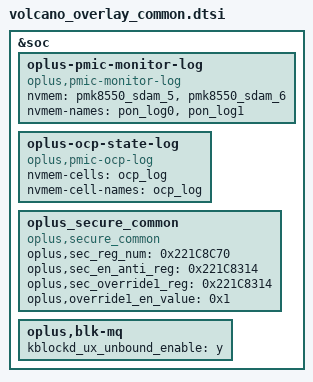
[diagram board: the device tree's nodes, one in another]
&soc {
    //add for 7635
   oplus-pmic-monitor-log {
        compatible = "oplus,pmic-monitor-log";
        nvmem = <&pmk8550_sdam_5>, <&pmk8550_sdam_6>;
        nvmem-names = "pon_log0", "pon_log1";
    };

   oplus-ocp-state-log {
        compatible = "oplus,pmic-ocp-log";
        nvmem-cells = <&ocp_log>;
        nvmem-cell-names = "ocp_log";
    };
    oplus_secure_common {
        compatible = "oplus,secure_common";
        oplus,sec_reg_num = <0x221C8C70>;
        oplus,sec_en_anti_reg = <0x221C8314>;
        oplus,sec_override1_reg = <0x221C8314>;
        oplus,override1_en_value = <0x1>;
    };

    oplus,blk-mq {
	kblockd_ux_unbound_enable = "y";
    };
};
